# STM32C552 register map
File version: 1.0.0
CPU: CM33 r0p4, little endian, MPU, FPU, 4 interrupt priority bits
Registers are 32-bit, read-write, reset 0x0 unless marked. A register's access mark holds for its fields unless they carry their own. Offsets are from the block's base; [hi:lo] are bit positions; {n}, {i} and the like mark numbered series; 'fields as' and 'values as' point back to an identical list.

## GTZC1 — Global privilege controller
Base 0x40032400
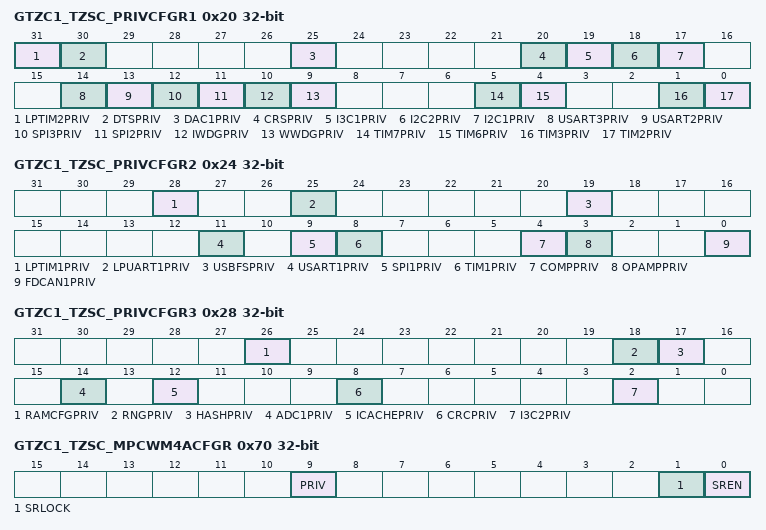
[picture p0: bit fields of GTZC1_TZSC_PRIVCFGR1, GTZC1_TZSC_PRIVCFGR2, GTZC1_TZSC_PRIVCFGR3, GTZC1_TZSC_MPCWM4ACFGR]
0x20 GTZC1_TZSC_PRIVCFGR1 — GTZC1 TZSC privilege configuration register 1
  [all] fields
    0=unprivileged; 1=privileged
  [31] LPTIM2PRIV — privileged access mode for LPTIM2
  [30] DTSPRIV — privileged access mode for DTS
  [25] DAC1PRIV — privileged access mode for DAC1
  [20] CRSPRIV — privileged access mode for CRS
  [19] I3C1PRIV — privileged access mode for I3C1
  [18] I2C2PRIV — privileged access mode for I2C2
  [17] I2C1PRIV — privileged access mode for I2C1
  [14] USART3PRIV — privileged access mode for USART3
  [13] USART2PRIV — privileged access mode for USART2
  [12] SPI3PRIV — privileged access mode for SPI3
  [11] SPI2PRIV — privileged access mode for SPI2
  [10] IWDGPRIV — privileged access mode for IWDG
  [9] WWDGPRIV — privileged access mode for WWDG
  [5] TIM7PRIV — privileged access mode for TIM7
  [4] TIM6PRIV — privileged access mode for TIM6
  [1] TIM3PRIV — privileged access mode for TIM3
  [0] TIM2PRIV — privileged access mode for TIM2
0x24 GTZC1_TZSC_PRIVCFGR2 — GTZC1 TZSC privilege configuration register 2
  [all] fields
    0=unprivileged; 1=privileged
  [28] LPTIM1PRIV — privileged access mode for LPTIM1
  [25] LPUART1PRIV — privileged access mode for LPUART
  [19] USBFSPRIV — privileged access mode for USBSF
  [11] USART1PRIV — privileged access mode for USART1
  [9] SPI1PRIV — privileged access mode for SPI1
  [8] TIM1PRIV — privileged access mode for TIM1
  [4] COMPPRIV — privileged access mode for COMP
  [3] OPAMPPRIV — privileged access mode for OPAMP
  [0] FDCAN1PRIV — privileged access mode for FDCAN1
0x28 GTZC1_TZSC_PRIVCFGR3 — GTZC1 TZSC privilege configuration register 3
  [all] fields
    0=unprivileged; 1=privileged
  [26] RAMCFGPRIV — privileged access mode for RAMSCFG
  [18] RNGPRIV — privileged access mode for RNG
  [17] HASHPRIV — privileged access mode for HASH
  [14] ADC1PRIV — privileged access mode for ADC1
  [12] ICACHEPRIV — privileged access mode for ICACHE
  [8] CRCPRIV — privileged access mode for CRC
  [2] I3C2PRIV — privileged access mode for I3C2
0x70 GTZC1_TZSC_MPCWM4ACFGR — GTZC1 TZSC BKPSRAM sub-region A watermark configuration register
  [9] PRIV — Privileged sub-region z This bit is taken into account only if SREN is set.
    0=Privileged and unprivileged accesses are granted in sub-region z; 1=Only privileged accesses are granted in sub-region z
  [1] SRLOCK — Sub-region z lock This bit, once set, can be cleared only by a system reset.
    0=GTZC1_TZSC_MPCWMzCFGR, GTZC1_TZSC_MPCWMAR and GTZC1_TZSC_MPCWMBR can be written; 1=Writes to GTZC1_TZSC_MPCWMzCFGR, GTZC1_TZSC_MPCWMAR and GTZC1_TZSC_MPCWMBR are ignored
  [0] SREN — Sub-region z enable
    0=Sub-region z is disabled. Access control of base region applies to any access between this sub-region start- and end-addresses.; 1=Sub-region z is enabled. Access control defined in GTZC1_TZSC_MPCWMzCFGR applies to any access between this sub-region start- and end-addresses, both defined in GTZC1_TZSC_MPCWMAR and GTZC1_TZSC_MPCWMBR.
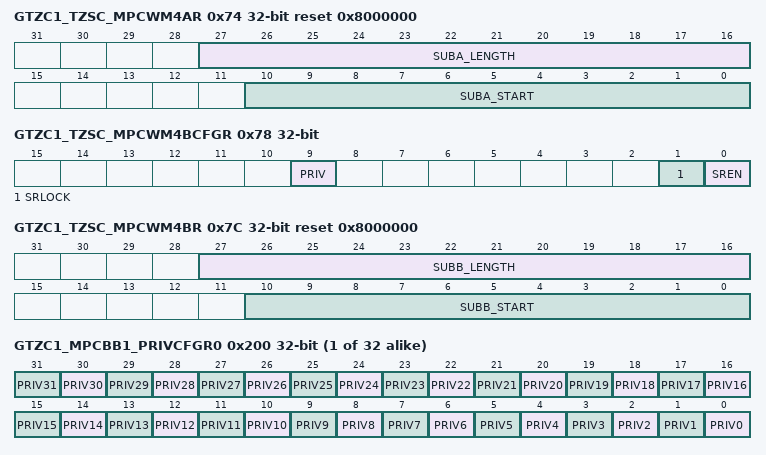
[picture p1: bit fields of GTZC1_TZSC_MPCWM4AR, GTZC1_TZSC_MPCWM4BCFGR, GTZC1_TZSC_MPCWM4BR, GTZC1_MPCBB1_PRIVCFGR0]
0x74 GTZC1_TZSC_MPCWM4AR reset 0x8000000 — GTZC1 TZSC BKPSRAM sub-region A watermark register
  [27:16] SUBA_LENGTH — Length of sub-region A This field defines the length of the sub-region A, to be multiplied by the granularity defined in Table 16. When SUBA_START + SUBA_LENGTH is higher than the maximum size allowed for the memory, a saturation of SUBA_LENGTH is applied automatically. If SUBA_LENGTH = 0, the sub-region A is disabled (SREN bit in GTZC1_TZSC_MPCMWACFGR is cleared).
  [10:0] SUBA_START — Start of sub-region A This field defines the address offset of the sub-region A, to be multiplied by the granularity defined in Table 16.
0x78 GTZC1_TZSC_MPCWM4BCFGR — GTZC1 TZSC BKPSRAM sub-region B watermark configuration register
  fields as GTZC1_TZSC_MPCWM4ACFGR
0x7C GTZC1_TZSC_MPCWM4BR reset 0x8000000 — GTZC1 TZSC BKPSRAM sub-region B watermark register
  [27:16] SUBB_LENGTH — Length of sub-region B This field defines the length of the sub-region B, to be multiplied by the granularity defined in Table 16. When SUBB_START + SUBB_LENGTH is higher than the maximum size allowed for the memory, a saturation of SUBB_LENGTH is applied automatically. If SUBB_LENGTH = 0, the sub-region B is disabled (SREN bit in GTZC1_TZSC_MPCMWBCFGR is cleared).
  [10:0] SUBB_START — Start of sub-region B This field defines the address offset of the sub-region B, to be multiplied by the granularity defined in Table 16.
{0x200+4i} GTZC1_MPCBB1_PRIVCFGR{i} (i=0..31) — GTZC1 SRAM1 MPCBB privileged configuration for super-block {i} register
  [all] fields
    0=Privileged and unprivileged access to block y, belonging to super-block x; 1=Only privileged access to block y, belonging to super-block x
  [n] PRIV{n} (n=0..31) — Privileged configuration for block y, belonging to super-block x (y = 31 to 0).
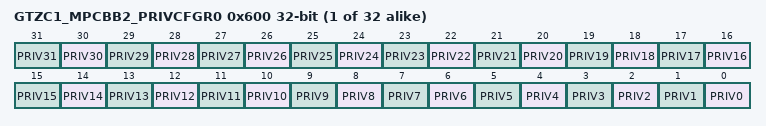
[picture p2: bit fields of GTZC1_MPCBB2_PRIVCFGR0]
{0x600+4i} GTZC1_MPCBB2_PRIVCFGR{i} (i=0..31) — GTZC1 SRAM2 MPCBB privileged configuration for super-block {i} register
  fields as GTZC1_MPCBB1_PRIVCFGR0
